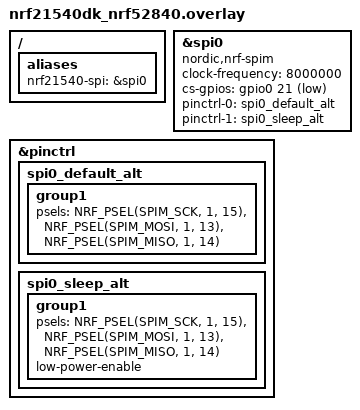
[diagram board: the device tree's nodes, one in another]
/ {
     aliases {
             nrf21540-spi = &spi0;
     };
};

&spi0 {
	compatible = "nordic,nrf-spim";
	status = "okay";
	clock-frequency = <8000000>;
	cs-gpios = <&gpio0 21 GPIO_ACTIVE_LOW>;
	pinctrl-0 = <&spi0_default_alt>;
	pinctrl-1 = <&spi0_sleep_alt>;
	pinctrl-names = "default", "sleep";
};

&pinctrl {
	spi0_default_alt: spi0_default_alt {
		group1 {
			psels = <NRF_PSEL(SPIM_SCK, 1, 15)>,
				<NRF_PSEL(SPIM_MOSI, 1, 13)>,
				<NRF_PSEL(SPIM_MISO, 1, 14)>;
		};
	};

	spi0_sleep_alt: spi0_sleep_alt {
		group1 {
			psels = <NRF_PSEL(SPIM_SCK, 1, 15)>,
				<NRF_PSEL(SPIM_MOSI, 1, 13)>,
				<NRF_PSEL(SPIM_MISO, 1, 14)>;
			low-power-enable;
		};
	};

};
